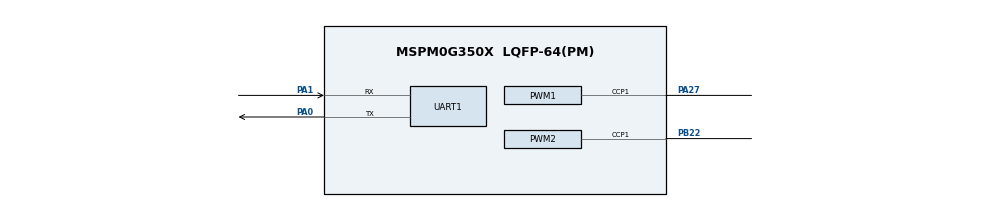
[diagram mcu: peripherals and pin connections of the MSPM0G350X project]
/**
 * @cliArgs --device "MSPM0G350X" --part "Default" --package "LQFP-64(PM)" --product "mspm0_sdk@2.10.00.04"
 * @versions {"tool":"1.26.2+4477"}
 */

/**
 * Import the modules used in this configuration.
 */
const ADC12  = scripting.addModule("/ti/driverlib/ADC12", {}, false);
const ADC121 = ADC12.addInstance();
const Board  = scripting.addModule("/ti/driverlib/Board");
const GPIO   = scripting.addModule("/ti/driverlib/GPIO", {}, false);
const GPIO1  = GPIO.addInstance();
const GPIO2  = GPIO.addInstance();
const GPIO3  = GPIO.addInstance();
const GPIO4  = GPIO.addInstance();
const PWM    = scripting.addModule("/ti/driverlib/PWM", {}, false);
const PWM1   = PWM.addInstance();
const PWM2   = PWM.addInstance();
const SYSCTL = scripting.addModule("/ti/driverlib/SYSCTL");
const TIMER  = scripting.addModule("/ti/driverlib/TIMER", {}, false);
const TIMER1 = TIMER.addInstance();
const UART   = scripting.addModule("/ti/driverlib/UART", {}, false);
const UART1  = UART.addInstance();

/**
 * Write custom configuration values to the imported modules.
 */
const divider2       = system.clockTree["HFCLK4MFPCLKDIV"];
divider2.divideValue = 2;

const divider6       = system.clockTree["PLL_CLK2X_DIV"];
divider6.divideValue = 4;

const divider7       = system.clockTree["PLL_PDIV"];
divider7.divideValue = 2;

const divider9       = system.clockTree["UDIV"];
divider9.divideValue = 2;

const gate7  = system.clockTree["MFCLKGATE"];
gate7.enable = true;

const gate8  = system.clockTree["MFPCLKGATE"];
gate8.enable = true;

const multiplier2         = system.clockTree["PLL_QDIV"];
multiplier2.multiplyValue = 10;

const mux8       = system.clockTree["HSCLKMUX"];
mux8.inputSelect = "HSCLKMUX_SYSPLL2X";

ADC121.$name                      = "ADC12_0";
ADC121.adcMem0chansel             = "DL_ADC12_INPUT_CHAN_1";
ADC121.sampleTime0                = "1 ms";
ADC121.peripheral.$assign         = "ADC0";
ADC121.peripheral.adcPin1.$assign = "PA26";
ADC121.adcPin1Config.$name        = "ti_driverlib_gpio_GPIOPinGeneric0";


GPIO1.$name                              = "GPIO_XUNJI";
GPIO1.associatedPins.create(7);
GPIO1.associatedPins[0].$name            = "PIN_0";
GPIO1.associatedPins[0].direction        = "INPUT";
GPIO1.associatedPins[0].internalResistor = "PULL_UP";
GPIO1.associatedPins[0].assignedPort     = "PORTB";
GPIO1.associatedPins[0].assignedPin      = "13";
GPIO1.associatedPins[1].$name            = "PIN_1";
GPIO1.associatedPins[1].direction        = "INPUT";
GPIO1.associatedPins[1].internalResistor = "PULL_UP";
GPIO1.associatedPins[1].assignedPort     = "PORTB";
GPIO1.associatedPins[1].assignedPin      = "14";
GPIO1.associatedPins[2].$name            = "PIN_2";
GPIO1.associatedPins[2].direction        = "INPUT";
GPIO1.associatedPins[2].internalResistor = "PULL_UP";
GPIO1.associatedPins[2].assignedPort     = "PORTB";
GPIO1.associatedPins[2].assignedPin      = "15";
GPIO1.associatedPins[3].$name            = "PIN_3";
GPIO1.associatedPins[3].direction        = "INPUT";
GPIO1.associatedPins[3].internalResistor = "PULL_UP";
GPIO1.associatedPins[3].assignedPort     = "PORTB";
GPIO1.associatedPins[3].assignedPin      = "16";
GPIO1.associatedPins[4].$name            = "PIN_4";
GPIO1.associatedPins[4].direction        = "INPUT";
GPIO1.associatedPins[4].internalResistor = "PULL_UP";
GPIO1.associatedPins[4].assignedPort     = "PORTB";
GPIO1.associatedPins[4].assignedPin      = "17";
GPIO1.associatedPins[5].$name            = "PIN_5";
GPIO1.associatedPins[5].direction        = "INPUT";
GPIO1.associatedPins[5].internalResistor = "PULL_UP";
GPIO1.associatedPins[5].assignedPort     = "PORTB";
GPIO1.associatedPins[5].assignedPin      = "18";
GPIO1.associatedPins[6].$name            = "PIN_6";
GPIO1.associatedPins[6].direction        = "INPUT";
GPIO1.associatedPins[6].internalResistor = "PULL_UP";
GPIO1.associatedPins[6].assignedPort     = "PORTB";
GPIO1.associatedPins[6].assignedPin      = "19";

GPIO2.$name                          = "GPIO_BUZZER";
GPIO2.associatedPins[0].$name        = "PIN";
GPIO2.associatedPins[0].assignedPort = "PORTB";
GPIO2.associatedPins[0].assignedPin  = "25";

GPIO3.$name                          = "GPIO_MOTOR";
GPIO3.associatedPins.create(4);
GPIO3.associatedPins[0].$name        = "A_1";
GPIO3.associatedPins[0].assignedPort = "PORTB";
GPIO3.associatedPins[0].assignedPin  = "2";
GPIO3.associatedPins[1].$name        = "A_2";
GPIO3.associatedPins[1].assignedPort = "PORTB";
GPIO3.associatedPins[1].assignedPin  = "3";
GPIO3.associatedPins[2].$name        = "B_1";
GPIO3.associatedPins[2].assignedPort = "PORTB";
GPIO3.associatedPins[2].assignedPin  = "4";
GPIO3.associatedPins[3].$name        = "B_2";
GPIO3.associatedPins[3].assignedPort = "PORTB";
GPIO3.associatedPins[3].assignedPin  = "5";

GPIO4.$name                          = "GPIO_OLED";
GPIO4.associatedPins.create(2);
GPIO4.associatedPins[0].$name        = "PIN_SDA";
GPIO4.associatedPins[0].assignedPort = "PORTB";
GPIO4.associatedPins[0].assignedPin  = "8";
GPIO4.associatedPins[1].$name        = "PIN_SCL";
GPIO4.associatedPins[1].assignedPort = "PORTB";
GPIO4.associatedPins[1].assignedPin  = "9";

PWM1.$name                      = "PWM_0";
PWM1.ccIndex                    = [1];
PWM1.ccp1PinConfig.$name        = "ti_driverlib_gpio_GPIOPinGeneric2";
PWM1.peripheral.$assign         = "TIMG7";
PWM1.peripheral.ccp1Pin.$assign = "PA27";
PWM1.PWM_CHANNEL_1.$name        = "ti_driverlib_pwm_PWMTimerCC0";

PWM2.$name                      = "PWM_1";
PWM2.ccIndex                    = [1];
PWM2.ccp1PinConfig.$name        = "ti_driverlib_gpio_GPIOPinGeneric4";
PWM2.peripheral.$assign         = "TIMG8";
PWM2.peripheral.ccp1Pin.$assign = "PB22";
PWM2.PWM_CHANNEL_1.$name        = "ti_driverlib_pwm_PWMTimerCC1";

SYSCTL.clockTreeEn = true;

TIMER1.$name              = "TIMER_0";
TIMER1.peripheral.$assign = "TIMA0";

UART1.$name                    = "UART_0";
UART1.targetBaudRate           = 230400;
UART1.enabledInterrupts        = ["RX"];
UART1.peripheral.$assign       = "UART0";
UART1.peripheral.rxPin.$assign = "PA1";
UART1.peripheral.txPin.$assign = "PA0";
UART1.txPinConfig.$name        = "ti_driverlib_gpio_GPIOPinGeneric1";
UART1.rxPinConfig.$name        = "ti_driverlib_gpio_GPIOPinGeneric3";

/**
 * Pinmux solution for unlocked pins/peripherals. This ensures that minor changes to the automatic solver in a future
 * version of the tool will not impact the pinmux you originally saw.  These lines can be completely deleted in order to
 * re-solve from scratch.
 */
Board.peripheral.$suggestSolution            = "DEBUGSS";
Board.peripheral.swclkPin.$suggestSolution   = "PA20";
Board.peripheral.swdioPin.$suggestSolution   = "PA19";
GPIO1.associatedPins[0].pin.$suggestSolution = "PB13";
GPIO1.associatedPins[1].pin.$suggestSolution = "PB14";
GPIO1.associatedPins[2].pin.$suggestSolution = "PB15";
GPIO1.associatedPins[3].pin.$suggestSolution = "PB16";
GPIO1.associatedPins[4].pin.$suggestSolution = "PB17";
GPIO1.associatedPins[5].pin.$suggestSolution = "PB18";
GPIO1.associatedPins[6].pin.$suggestSolution = "PB19";
GPIO2.associatedPins[0].pin.$suggestSolution = "PB25";
GPIO3.associatedPins[0].pin.$suggestSolution = "PB2";
GPIO3.associatedPins[1].pin.$suggestSolution = "PB3";
GPIO3.associatedPins[2].pin.$suggestSolution = "PB4";
GPIO3.associatedPins[3].pin.$suggestSolution = "PB5";
GPIO4.associatedPins[0].pin.$suggestSolution = "PB8";
GPIO4.associatedPins[1].pin.$suggestSolution = "PB9";
